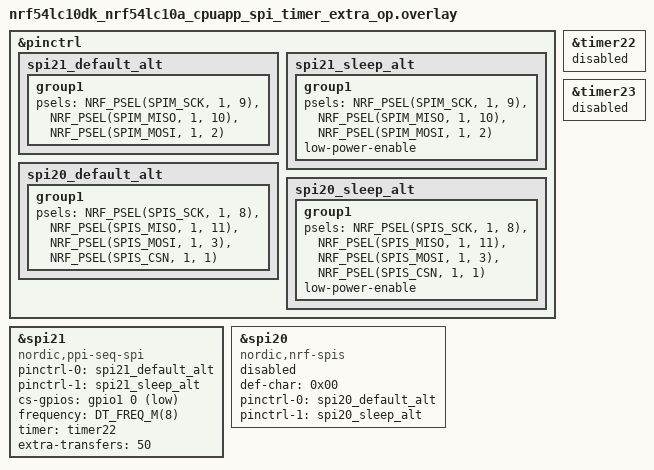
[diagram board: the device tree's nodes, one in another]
/*
 * Copyright (c) 2026 Nordic Semiconductor ASA
 *
 * SPDX-License-Identifier: LicenseRef-Nordic-5-Clause
 */

/* Test requires loopbacks:
 * - between P1.09 and P1.08
 * - between P1.10 and P1.11
 * - between P1.02 and P1.03
 * - between P1.00 and P1.01
 */

&pinctrl {
	spi21_default_alt: spi21_default_alt {
		group1 {
			psels = <NRF_PSEL(SPIM_SCK, 1, 9)>,
				<NRF_PSEL(SPIM_MISO, 1, 10)>,
				<NRF_PSEL(SPIM_MOSI, 1, 2)>;
		};
	};

	spi21_sleep_alt: spi21_sleep_alt {
		group1 {
			psels = <NRF_PSEL(SPIM_SCK, 1, 9)>,
				<NRF_PSEL(SPIM_MISO, 1, 10)>,
				<NRF_PSEL(SPIM_MOSI, 1, 2)>;
			low-power-enable;
		};
	};

	spi20_default_alt: spi20_default_alt {
		group1 {
			psels = <NRF_PSEL(SPIS_SCK, 1, 8)>,
				<NRF_PSEL(SPIS_MISO, 1, 11)>,
				<NRF_PSEL(SPIS_MOSI, 1, 3)>,
				<NRF_PSEL(SPIS_CSN, 1, 1)>;
		};
	};

	spi20_sleep_alt: spi20_sleep_alt {
		group1 {
			psels = <NRF_PSEL(SPIS_SCK, 1, 8)>,
				<NRF_PSEL(SPIS_MISO, 1, 11)>,
				<NRF_PSEL(SPIS_MOSI, 1, 3)>,
				<NRF_PSEL(SPIS_CSN, 1, 1)>;
			low-power-enable;
		};
	};
};

/* Used as trigger by the PPI sequencer. */
&timer22 {
	status = "reserved";
};

test_timer: &timer23 {
	status = "reserved";
};

dut: &spi21 {
	compatible = "nordic,ppi-seq-spi";
	status = "okay";
	pinctrl-0 = <&spi21_default_alt>;
	pinctrl-1 = <&spi21_sleep_alt>;
	pinctrl-names = "default", "sleep";
	cs-gpios = <&gpio1 0 GPIO_ACTIVE_LOW>;
	frequency = <DT_FREQ_M(8)>;
	timer = <&timer22>;
	extra-transfers = <50>;
};

tester: &spi20 {
	compatible = "nordic,nrf-spis";
	status = "reserved";
	def-char = <0x00>;
	pinctrl-0 = <&spi20_default_alt>;
	pinctrl-1 = <&spi20_sleep_alt>;
	pinctrl-names = "default", "sleep";
	/delete-property/ rx-delay-supported;
	/delete-property/ rx-delay;
};
